AUTOSAR XML (schema 00046)
standard types defined: uint8
package /DataTypes/ApplicationDataTypes
  app type AdtName1: category=VALUE
package /DataTypes/ImplementationDataTypes
  impl type IdtName1: category=VALUE, base-type=uint8
package /SoftwareTypes/ComponentTypes
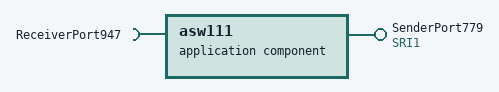
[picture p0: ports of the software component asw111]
  application sw component type asw111
    provide port SenderPort779: provided-interface=SRI1
    require port ReceiverPort947
package /SoftwareTypes/Interfaces
  sender receiver interface SRI1
    data DE1: type=IdtName1
